AUTOSAR XML (schema 4-3-0)
package /Impl_CGW_ARPkg
  swc implementation Impl_SWC_CGW_type: programming-language=C, sw-version=1.0.0, vendor-id=0, behavior=SWC_CGW_type_IB
    code-descriptors:
      code SRC: artifact-descriptors=autosar-engineering-object={short-label=EngObject, category=SWSRC}
    resource consumption ResourceConsumption
      memory section MEM_SWC_CGW_CAL: size=0, sw-addrmethod=CAL, symbol=CAL
      memory section MEM_SWC_CGW_CODE: size=0, sw-addrmethod=CODE, symbol=CODE
package /SWC_CGW_ARPkg
  trigger interface IF_ExtTrig_CGW
    trigger Trig_CGW
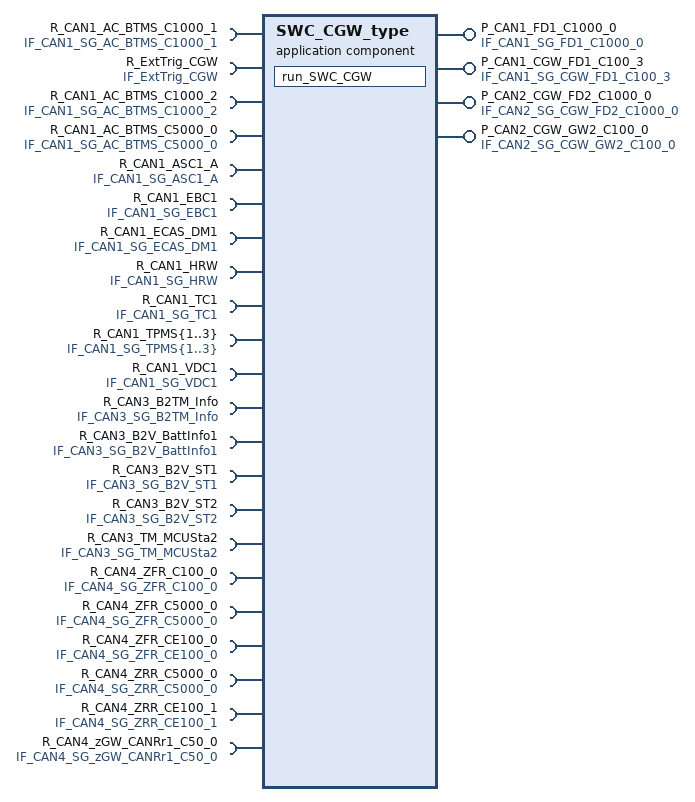
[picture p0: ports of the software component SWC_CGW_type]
  application sw component type SWC_CGW_type
    4 x provide port:
      P_CAN1_FD1_C1000_0: provided-interface=IF_CAN1_SG_FD1_C1000_0
      P_CAN1_CGW_FD1_C100_3: provided-interface=IF_CAN1_SG_CGW_FD1_C100_3
      P_CAN2_CGW_FD2_C1000_0: provided-interface=IF_CAN2_SG_CGW_FD2_C1000_0
      P_CAN2_CGW_GW2_C100_0: provided-interface=IF_CAN2_SG_CGW_GW2_C100_0
    24 x require port:
      R_CAN1_AC_BTMS_C1000_1: required-interface=IF_CAN1_SG_AC_BTMS_C1000_1
      R_ExtTrig_CGW: required-interface=IF_ExtTrig_CGW
      R_CAN1_AC_BTMS_C1000_2: required-interface=IF_CAN1_SG_AC_BTMS_C1000_2
      R_CAN1_AC_BTMS_C5000_0: required-interface=IF_CAN1_SG_AC_BTMS_C5000_0
      R_CAN1_ASC1_A: required-interface=IF_CAN1_SG_ASC1_A
      R_CAN1_EBC1: required-interface=IF_CAN1_SG_EBC1
      R_CAN1_ECAS_DM1: required-interface=IF_CAN1_SG_ECAS_DM1
      R_CAN1_HRW: required-interface=IF_CAN1_SG_HRW
      R_CAN1_TC1: required-interface=IF_CAN1_SG_TC1
      R_CAN1_TPMS{1..3}: required-interface=IF_CAN1_SG_TPMS{1..3}
      R_CAN1_VDC1: required-interface=IF_CAN1_SG_VDC1
      R_CAN3_B2TM_Info: required-interface=IF_CAN3_SG_B2TM_Info
      R_CAN3_B2V_BattInfo1: required-interface=IF_CAN3_SG_B2V_BattInfo1
      R_CAN3_B2V_ST1: required-interface=IF_CAN3_SG_B2V_ST1
      R_CAN3_B2V_ST2: required-interface=IF_CAN3_SG_B2V_ST2
      R_CAN3_TM_MCUSta2: required-interface=IF_CAN3_SG_TM_MCUSta2
      R_CAN4_ZFR_C100_0: required-interface=IF_CAN4_SG_ZFR_C100_0
      R_CAN4_ZFR_C5000_0: required-interface=IF_CAN4_SG_ZFR_C5000_0
      R_CAN4_ZFR_CE100_0: required-interface=IF_CAN4_SG_ZFR_CE100_0
      R_CAN4_ZRR_C5000_0: required-interface=IF_CAN4_SG_ZRR_C5000_0
      R_CAN4_ZRR_CE100_1: required-interface=IF_CAN4_SG_ZRR_CE100_1
      R_CAN4_zGW_CANRr1_C50_0: required-interface=IF_CAN4_SG_zGW_CANRr1_C50_0
    behavior SWC_CGW_type_IB: handle-termination-and-restart=NO-SUPPORT
      external trigger occurred event ETE_CGW: start-on-event=run_SWC_CGW, trigger=R_ExtTrig_CGW.Trig_CGW
      runnable run_SWC_CGW
        data-read-access:
          23 x access:
            DA_R_CAN1_AC_BTMS_C1000_1: accessed-variable=R_CAN1_AC_BTMS_C1000_1.CAN1_SG_AC_BTMS_C1000_1
            DA_R_CAN1_AC_BTMS_C1000_2: accessed-variable=R_CAN1_AC_BTMS_C1000_2.CAN1_SG_AC_BTMS_C1000_2
            DA_R_CAN1_AC_BTMS_C5000_0: accessed-variable=R_CAN1_AC_BTMS_C5000_0.CAN1_SG_AC_BTMS_C5000_0
            DA_R_CAN1_ASC1_A: accessed-variable=R_CAN1_ASC1_A.CAN1_SG_ASC1_A
            DA_R_CAN1_EBC1: accessed-variable=R_CAN1_EBC1.CAN1_SG_EBC1
            DA_R_CAN1_ECAS_DM1: accessed-variable=R_CAN1_ECAS_DM1.CAN1_SG_ECAS_DM1
            DA_R_CAN1_HRW: accessed-variable=R_CAN1_HRW.CAN1_SG_HRW
            DA_R_CAN1_TC1: accessed-variable=R_CAN1_TC1.CAN1_SG_TC1
            DA_R_CAN1_TPMS{1..3}: accessed-variable=R_CAN1_TPMS{1..3}.CAN1_SG_TPMS{1..3}
            DA_R_CAN1_VDC1: accessed-variable=R_CAN1_VDC1.CAN1_SG_VDC1
            DA_R_CAN3_B2TM_Info: accessed-variable=R_CAN3_B2TM_Info.CAN3_SG_B2TM_Info
            DA_R_CAN3_B2V_BattInfo1: accessed-variable=R_CAN3_B2V_BattInfo1.CAN3_SG_B2V_BattInfo1
            DA_R_CAN3_B2V_ST1: accessed-variable=R_CAN3_B2V_ST1.CAN3_SG_B2V_ST1
            DA_R_CAN3_B2V_ST2: accessed-variable=R_CAN3_B2V_ST2.CAN3_SG_B2V_ST2
            DA_R_CAN3_TM_MCUSta2: accessed-variable=R_CAN3_TM_MCUSta2.CAN3_SG_TM_MCUSta2
            DA_R_CAN4_ZFR_C100_0: accessed-variable=R_CAN4_ZFR_C100_0.CAN4_SG_ZFR_C100_0
            DA_R_CAN4_ZFR_C5000_0: accessed-variable=R_CAN4_ZFR_C5000_0.CAN4_SG_ZFR_C5000_0
            DA_R_CAN4_ZFR_CE100_0: accessed-variable=R_CAN4_ZFR_CE100_0.CAN4_SG_ZFR_CE100_0
            DA_R_CAN4_ZRR_C5000_0: accessed-variable=R_CAN4_ZRR_C5000_0.CAN4_SG_ZRR_C5000_0
            DA_R_CAN4_ZRR_CE100_1: accessed-variable=R_CAN4_ZRR_CE100_1.CAN4_SG_ZRR_CE100_1
            DA_R_CAN4_zGW_CANRr1_C50_0: accessed-variable=R_CAN4_zGW_CANRr1_C50_0.CAN4_SG_zGW_CANRr1_C50_0
        data-write-access:
          4 x access:
            DA_P_CAN1_FD1_C1000_0: accessed-variable=P_CAN1_FD1_C1000_0.CAN1_SG_FD1_C1000_0
            DA_P_CAN1_CGW_FD1_C100_3: accessed-variable=P_CAN1_CGW_FD1_C100_3.CAN1_SG_CGW_FD1_C100_3
            DA_P_CAN2_CGW_FD2_C1000_0: accessed-variable=P_CAN2_CGW_FD2_C1000_0.CAN2_SG_CGW_FD2_C1000_0
            DA_P_CAN2_CGW_GW2_C100_0: accessed-variable=P_CAN2_CGW_GW2_C100_0.CAN2_SG_CGW_GW2_C100_0
